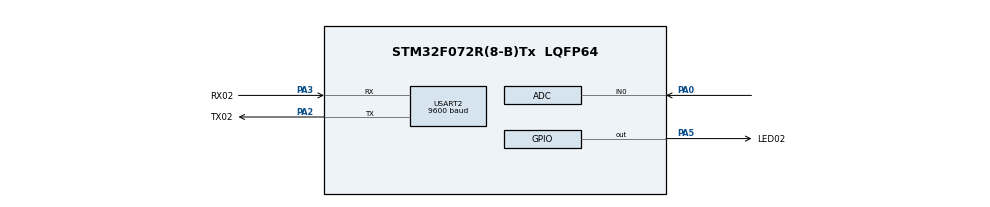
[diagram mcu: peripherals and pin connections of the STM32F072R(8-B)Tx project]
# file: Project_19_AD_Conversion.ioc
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Mcu.Family=STM32F0
Mcu.Name=STM32F072R(8-B)Tx
Mcu.Package=LQFP64
NVIC.ADC1_COMP_IRQn=true\:0\:0\:false\:false\:true\:true\:true\:true
NVIC.USART2_IRQn=true\:0\:0\:false\:false\:true\:true\:true\:true
PA0.Mode=IN0
PA0.Signal=ADC_IN0
PA13.Mode=Serial_Wire
PA13.Signal=SYS_SWDIO
PA14.Mode=Serial_Wire
PA14.Signal=SYS_SWCLK
PA2.GPIO_Label=TX02
PA2.Mode=Asynchronous
PA2.Signal=USART2_TX
PA3.GPIO_Label=RX02
PA3.Mode=Asynchronous
PA3.Signal=USART2_RX
PA5.GPIO_Label=LED02
PA5.Signal=GPIO_Output
ProjectManager.HeapSize=0x200
ProjectManager.StackSize=0x400
ProjectManager.TargetToolchain=STM32CubeIDE
USART2.BaudRate=9600
USART2.VirtualMode-Asynchronous=VM_ASYNC
board=custom

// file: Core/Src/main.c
/* USER CODE BEGIN Header */
/**
  ******************************************************************************
  * @file           : main.c
  * @brief          : Main program body
  ******************************************************************************
  * @attention
  *
  * Copyright (c) 2022 STMicroelectronics.
  * All rights reserved.
  *
  * This software is licensed under terms that can be found in the LICENSE file
  * in the root directory of this software component.
  * If no LICENSE file comes with this software, it is provided AS-IS.
  *
  ******************************************************************************
  */
/* USER CODE END Header */
#include "main.h"

/* USER CODE BEGIN Includes */
#include "stdio.h"
#include "stdlib.h"

/* USER CODE END Includes */

ADC_HandleTypeDef hadc;

UART_HandleTypeDef huart2;

void SystemClock_Config(void);
static void MX_GPIO_Init(void);
static void MX_ADC_Init(void);
static void MX_USART2_UART_Init(void);

/* USER CODE BEGIN PFP */

void Read_Temperatur()
{

	uint16_t raw;
	char msg[16] = "";

	HAL_ADC_Start(&hadc);

	HAL_ADC_PollForConversion(&hadc,100);

	raw = HAL_ADC_GetValue(&hadc);

	HAL_UART_Transmit(&huart2,raw,sizeof raw,100);

	HAL_Delay(50);

}

/* USER CODE END PFP */

int main(void)
{

  /* MCU Configuration--------------------------------------------------------*/

  /* Reset of all peripherals, Initializes the Flash interface and the Systick. */
  HAL_Init();

  /* Configure the system clock */
  SystemClock_Config();

  /* Initialize all configured peripherals */
  MX_GPIO_Init();
  MX_ADC_Init();
  MX_USART2_UART_Init();

  /* Infinite loop */
  while (1)
  {

    /* USER CODE BEGIN 3 */
	  Read_Temperatur();
	  HAL_Delay(50);

  }
  /* USER CODE END 3 */
}

void SystemClock_Config(void)
{
  RCC_OscInitTypeDef RCC_OscInitStruct = {0};
  RCC_ClkInitTypeDef RCC_ClkInitStruct = {0};
  RCC_PeriphCLKInitTypeDef PeriphClkInit = {0};

  /** Initializes the RCC Oscillators according to the specified parameters
  * in the RCC_OscInitTypeDef structure.
  */
  RCC_OscInitStruct.OscillatorType = RCC_OSCILLATORTYPE_HSI|RCC_OSCILLATORTYPE_HSI14;
  RCC_OscInitStruct.HSIState = RCC_HSI_ON;
  RCC_OscInitStruct.HSI14State = RCC_HSI14_ON;
  RCC_OscInitStruct.HSICalibrationValue = RCC_HSICALIBRATION_DEFAULT;
  RCC_OscInitStruct.HSI14CalibrationValue = 16;
  RCC_OscInitStruct.PLL.PLLState = RCC_PLL_NONE;
  if (HAL_RCC_OscConfig(&RCC_OscInitStruct) != HAL_OK)
  {
    Error_Handler();
  }

  /** Initializes the CPU, AHB and APB buses clocks
  */
  RCC_ClkInitStruct.ClockType = RCC_CLOCKTYPE_HCLK|RCC_CLOCKTYPE_SYSCLK
                              |RCC_CLOCKTYPE_PCLK1;
  RCC_ClkInitStruct.SYSCLKSource = RCC_SYSCLKSOURCE_HSI;
  RCC_ClkInitStruct.AHBCLKDivider = RCC_SYSCLK_DIV1;
  RCC_ClkInitStruct.APB1CLKDivider = RCC_HCLK_DIV1;

  if (HAL_RCC_ClockConfig(&RCC_ClkInitStruct, FLASH_LATENCY_0) != HAL_OK)
  {
    Error_Handler();
  }
  PeriphClkInit.PeriphClockSelection = RCC_PERIPHCLK_USART2;
  PeriphClkInit.Usart2ClockSelection = RCC_USART2CLKSOURCE_PCLK1;
  if (HAL_RCCEx_PeriphCLKConfig(&PeriphClkInit) != HAL_OK)
  {
    Error_Handler();
  }
}

static void MX_ADC_Init(void)
{

  ADC_ChannelConfTypeDef sConfig = {0};

  /** Configure the global features of the ADC (Clock, Resolution, Data Alignment and number of conversion)
  */
  hadc.Instance = ADC1;
  hadc.Init.ClockPrescaler = ADC_CLOCK_ASYNC_DIV1;
  hadc.Init.Resolution = ADC_RESOLUTION_12B;
  hadc.Init.DataAlign = ADC_DATAALIGN_RIGHT;
  hadc.Init.ScanConvMode = ADC_SCAN_DIRECTION_FORWARD;
  hadc.Init.EOCSelection = ADC_EOC_SINGLE_CONV;
  hadc.Init.LowPowerAutoWait = DISABLE;
  hadc.Init.LowPowerAutoPowerOff = DISABLE;
  hadc.Init.ContinuousConvMode = DISABLE;
  hadc.Init.DiscontinuousConvMode = DISABLE;
  hadc.Init.ExternalTrigConv = ADC_SOFTWARE_START;
  hadc.Init.ExternalTrigConvEdge = ADC_EXTERNALTRIGCONVEDGE_NONE;
  hadc.Init.DMAContinuousRequests = DISABLE;
  hadc.Init.Overrun = ADC_OVR_DATA_PRESERVED;
  if (HAL_ADC_Init(&hadc) != HAL_OK)
  {
    Error_Handler();
  }

  /** Configure for the selected ADC regular channel to be converted.
  */
  sConfig.Channel = ADC_CHANNEL_0;
  sConfig.Rank = ADC_RANK_CHANNEL_NUMBER;
  sConfig.SamplingTime = ADC_SAMPLETIME_1CYCLE_5;
  if (HAL_ADC_ConfigChannel(&hadc, &sConfig) != HAL_OK)
  {
    Error_Handler();
  }

}

static void MX_USART2_UART_Init(void)
{

  huart2.Instance = USART2;
  huart2.Init.BaudRate = 9600;
  huart2.Init.WordLength = UART_WORDLENGTH_8B;
  huart2.Init.StopBits = UART_STOPBITS_1;
  huart2.Init.Parity = UART_PARITY_NONE;
  huart2.Init.Mode = UART_MODE_TX_RX;
  huart2.Init.HwFlowCtl = UART_HWCONTROL_NONE;
  huart2.Init.OverSampling = UART_OVERSAMPLING_16;
  huart2.Init.OneBitSampling = UART_ONE_BIT_SAMPLE_DISABLE;
  huart2.AdvancedInit.AdvFeatureInit = UART_ADVFEATURE_NO_INIT;
  if (HAL_UART_Init(&huart2) != HAL_OK)
  {
    Error_Handler();
  }

}

static void MX_GPIO_Init(void)
{
  GPIO_InitTypeDef GPIO_InitStruct = {0};

  /* GPIO Ports Clock Enable */
  __HAL_RCC_GPIOA_CLK_ENABLE();

  /*Configure GPIO pin Output Level */
  HAL_GPIO_WritePin(LED02_GPIO_Port, LED02_Pin, GPIO_PIN_RESET);

  /*Configure GPIO pin : LED02_Pin */
  GPIO_InitStruct.Pin = LED02_Pin;
  GPIO_InitStruct.Mode = GPIO_MODE_OUTPUT_PP;
  GPIO_InitStruct.Pull = GPIO_NOPULL;
  GPIO_InitStruct.Speed = GPIO_SPEED_FREQ_LOW;
  HAL_GPIO_Init(LED02_GPIO_Port, &GPIO_InitStruct);

}

void Error_Handler(void)
{
  __disable_irq();
  while (1)
  {
  }
}
